# LRFDPBE32 register map
Vendor: Texas Instruments
Peripheral module from a debugger description file (folder CC27xxx10).
Registers are 32-bit, access per field, reset 0x0 unless marked. A register's access mark holds for its fields unless they carry their own. Offsets are as the file gives them; lines under a group give offsets from that group; [hi:lo] are bit positions; {n}, {i} and the like mark numbered series; 'fields as' and 'values as' point back to an identical list; <NAME> marks a mode.

## LRFDPBE32
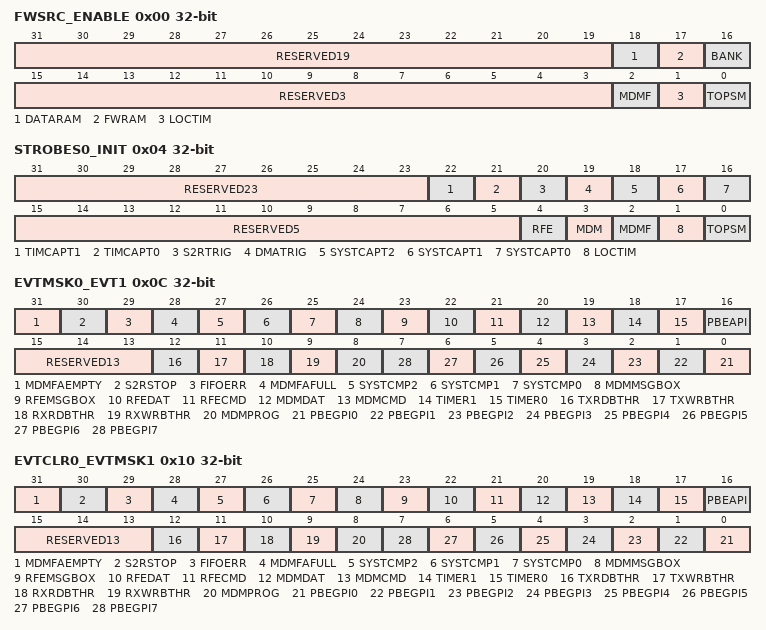
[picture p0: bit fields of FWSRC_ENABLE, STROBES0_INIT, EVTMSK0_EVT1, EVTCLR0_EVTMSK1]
0x00 FWSRC_ENABLE — Internal. Only to be used through TI provided API.
  [31:19] RESERVED19 ro — Internal. Only to be used through TI provided API.
  [18] DATARAM rw — Internal. Only to be used through TI provided API.
    1=S2RRAM (Internal. Only to be used through TI provided API.); 0=PBERAM (Internal. Only to be used through TI provided API.)
  [17] FWRAM rw — Internal. Only to be used through TI provided API.
    values as DATARAM
  [16] BANK rw — Internal. Only to be used through TI provided API.
    1=ONE (Internal. Only to be used through TI provided API.); 0=ZERO (Internal. Only to be used through TI provided API.)
  [15:3] RESERVED3 ro — Internal. Only to be used through TI provided API.
  [2] MDMF rw — Internal. Only to be used through TI provided API.
    1=EN (Internal. Only to be used through TI provided API.); 0=DIS (Internal. Only to be used through TI provided API.)
  [1] LOCTIM rw — Internal. Only to be used through TI provided API.
    values as MDMF
  [0] TOPSM rw — Internal. Only to be used through TI provided API.
    values as MDMF
0x04 STROBES0_INIT — Internal. Only to be used through TI provided API.
  [31:23] RESERVED23 ro — Internal. Only to be used through TI provided API.
  [22] TIMCAPT1 wo — Internal. Only to be used through TI provided API.
    values as FWSRC_ENABLE.BANK
  [21] TIMCAPT0 wo — Internal. Only to be used through TI provided API.
    values as FWSRC_ENABLE.BANK
  [20] S2RTRIG wo — Internal. Only to be used through TI provided API.
    1=ARM (Internal. Only to be used through TI provided API.); 0=NO_EFFECT (Internal. Only to be used through TI provided API.)
  [19] DMATRIG wo — Internal. Only to be used through TI provided API.
    values as S2RTRIG
  [18] SYSTCAPT2 wo — Internal. Only to be used through TI provided API.
    values as FWSRC_ENABLE.BANK
  [17] SYSTCAPT1 wo — Internal. Only to be used through TI provided API.
    values as FWSRC_ENABLE.BANK
  [16] SYSTCAPT0 wo — Internal. Only to be used through TI provided API.
    values as FWSRC_ENABLE.BANK
  [15:5] RESERVED5 ro — Internal. Only to be used through TI provided API.
  [4] RFE wo — Internal. Only to be used through TI provided API.
    1=RESET (Internal. Only to be used through TI provided API.); 0=NO_EFFECT (Internal. Only to be used through TI provided API.)
  [3] MDM wo — Internal. Only to be used through TI provided API.
    values as RFE
  [2] MDMF wo — Internal. Only to be used through TI provided API.
    values as RFE
  [1] LOCTIM wo — Internal. Only to be used through TI provided API.
    values as RFE
  [0] TOPSM wo — Internal. Only to be used through TI provided API.
    values as RFE
0x08 EVT0_IRQ — Internal. Only to be used through TI provided API.
  [31] MDMFAEMPTY ro — Internal. Only to be used through TI provided API.
    values as FWSRC_ENABLE.BANK
  [30] S2RSTOP ro — Internal. Only to be used through TI provided API.
    values as FWSRC_ENABLE.BANK
  [29] FIFOERR ro — Internal. Only to be used through TI provided API.
    values as FWSRC_ENABLE.BANK
  [28] MDMFAFULL ro — Internal. Only to be used through TI provided API.
    values as FWSRC_ENABLE.BANK
  [27] SYSTCMP2 ro — Internal. Only to be used through TI provided API.
    values as FWSRC_ENABLE.BANK
  [26] SYSTCMP1 ro — Internal. Only to be used through TI provided API.
    values as FWSRC_ENABLE.BANK
  [25] SYSTCMP0 ro — Internal. Only to be used through TI provided API.
    values as FWSRC_ENABLE.BANK
  [24] MDMMSGBOX ro — Internal. Only to be used through TI provided API.
    values as FWSRC_ENABLE.BANK
  [23] RFEMSGBOX ro — Internal. Only to be used through TI provided API.
    values as FWSRC_ENABLE.BANK
  [22] RFEDAT ro — Internal. Only to be used through TI provided API.
    values as FWSRC_ENABLE.BANK
  [21] RFECMD ro — Internal. Only to be used through TI provided API.
    values as FWSRC_ENABLE.BANK
  [20] MDMDAT ro — Internal. Only to be used through TI provided API.
    values as FWSRC_ENABLE.BANK
  [19] MDMCMD ro — Internal. Only to be used through TI provided API.
    values as FWSRC_ENABLE.BANK
  [18] TIMER1 ro — Internal. Only to be used through TI provided API.
    values as FWSRC_ENABLE.BANK
  [17] TIMER0 ro — Internal. Only to be used through TI provided API.
    values as FWSRC_ENABLE.BANK
  [16] PBEAPI ro — Internal. Only to be used through TI provided API.
    values as FWSRC_ENABLE.BANK
  [n] SOFT{n} wo (n=0..15) — Internal. Only to be used through TI provided API.
    1=ON (Internal. Only to be used through TI provided API.); 0=OFF (Internal. Only to be used through TI provided API.)
  [9:0] RESERVED0 ro — Internal. Only to be used through TI provided API.
0x0C EVTMSK0_EVT1 — Internal. Only to be used through TI provided API.
  [31] MDMFAEMPTY rw — Internal. Only to be used through TI provided API.
    values as FWSRC_ENABLE.MDMF
  [30] S2RSTOP rw — Internal. Only to be used through TI provided API.
    values as FWSRC_ENABLE.MDMF
  [29] FIFOERR rw — Internal. Only to be used through TI provided API.
    values as FWSRC_ENABLE.MDMF
  [28] MDMFAFULL rw — Internal. Only to be used through TI provided API.
    values as FWSRC_ENABLE.MDMF
  [27] SYSTCMP2 rw — Internal. Only to be used through TI provided API.
    values as FWSRC_ENABLE.MDMF
  [26] SYSTCMP1 rw — Internal. Only to be used through TI provided API.
    values as FWSRC_ENABLE.MDMF
  [25] SYSTCMP0 rw — Internal. Only to be used through TI provided API.
    values as FWSRC_ENABLE.MDMF
  [24] MDMMSGBOX rw — Internal. Only to be used through TI provided API.
    values as FWSRC_ENABLE.MDMF
  [23] RFEMSGBOX rw — Internal. Only to be used through TI provided API.
    values as FWSRC_ENABLE.MDMF
  [22] RFEDAT rw — Internal. Only to be used through TI provided API.
    values as FWSRC_ENABLE.MDMF
  [21] RFECMD rw — Internal. Only to be used through TI provided API.
    values as FWSRC_ENABLE.MDMF
  [20] MDMDAT rw — Internal. Only to be used through TI provided API.
    values as FWSRC_ENABLE.MDMF
  [19] MDMCMD rw — Internal. Only to be used through TI provided API.
    values as FWSRC_ENABLE.MDMF
  [18] TIMER1 rw — Internal. Only to be used through TI provided API.
    values as FWSRC_ENABLE.MDMF
  [17] TIMER0 rw — Internal. Only to be used through TI provided API.
    values as FWSRC_ENABLE.MDMF
  [16] PBEAPI rw — Internal. Only to be used through TI provided API.
    values as FWSRC_ENABLE.MDMF
  [15:13] RESERVED13 ro — Internal. Only to be used through TI provided API.
  [12] TXRDBTHR ro — Internal. Only to be used through TI provided API.
    1=MET (Internal. Only to be used through TI provided API.); 0=BELOW (Internal. Only to be used through TI provided API.)
  [11] TXWRBTHR ro — Internal. Only to be used through TI provided API.
    values as TXRDBTHR
  [10] RXRDBTHR ro — Internal. Only to be used through TI provided API.
    values as TXRDBTHR
  [9] RXWRBTHR ro — Internal. Only to be used through TI provided API.
    values as TXRDBTHR
  [8] MDMPROG ro — Internal. Only to be used through TI provided API.
    values as FWSRC_ENABLE.BANK
  [n] PBEGPI{n} ro (n=0..7) — Internal. Only to be used through TI provided API.
    values as FWSRC_ENABLE.BANK
0x10 EVTCLR0_EVTMSK1 — Internal. Only to be used through TI provided API.
  [31] MDMFAEMPTY wo — Internal. Only to be used through TI provided API.
    1=CLEAR (Internal. Only to be used through TI provided API.); 0=RETAIN (Internal. Only to be used through TI provided API.)
  [30] S2RSTOP wo — Internal. Only to be used through TI provided API.
    values as MDMFAEMPTY
  [29] FIFOERR wo — Internal. Only to be used through TI provided API.
    values as MDMFAEMPTY
  [28] MDMFAFULL wo — Internal. Only to be used through TI provided API.
    values as MDMFAEMPTY
  [27] SYSTCMP2 wo — Internal. Only to be used through TI provided API.
    values as MDMFAEMPTY
  [26] SYSTCMP1 wo — Internal. Only to be used through TI provided API.
    values as MDMFAEMPTY
  [25] SYSTCMP0 wo — Internal. Only to be used through TI provided API.
    values as MDMFAEMPTY
  [24] MDMMSGBOX wo — Internal. Only to be used through TI provided API.
    values as MDMFAEMPTY
  [23] RFEMSGBOX wo — Internal. Only to be used through TI provided API.
    values as MDMFAEMPTY
  [22] RFEDAT wo — Internal. Only to be used through TI provided API.
    values as MDMFAEMPTY
  [21] RFECMD wo — Internal. Only to be used through TI provided API.
    values as MDMFAEMPTY
  [20] MDMDAT wo — Internal. Only to be used through TI provided API.
    values as MDMFAEMPTY
  [19] MDMCMD wo — Internal. Only to be used through TI provided API.
    values as MDMFAEMPTY
  [18] TIMER1 wo — Internal. Only to be used through TI provided API.
    values as MDMFAEMPTY
  [17] TIMER0 wo — Internal. Only to be used through TI provided API.
    values as MDMFAEMPTY
  [16] PBEAPI wo — Internal. Only to be used through TI provided API.
    values as MDMFAEMPTY
  [15:13] RESERVED13 ro — Internal. Only to be used through TI provided API.
  [12] TXRDBTHR rw — Internal. Only to be used through TI provided API.
    values as FWSRC_ENABLE.MDMF
  [11] TXWRBTHR rw — Internal. Only to be used through TI provided API.
    values as FWSRC_ENABLE.MDMF
  [10] RXRDBTHR rw — Internal. Only to be used through TI provided API.
    values as FWSRC_ENABLE.MDMF
  [9] RXWRBTHR rw — Internal. Only to be used through TI provided API.
    values as FWSRC_ENABLE.MDMF
  [8] MDMPROG rw — Internal. Only to be used through TI provided API.
    values as FWSRC_ENABLE.MDMF
  [n] PBEGPI{n} rw (n=0..7) — Internal. Only to be used through TI provided API.
    values as FWSRC_ENABLE.MDMF
0x14 PDREQ_EVTCLR1 — Internal. Only to be used through TI provided API.
  [31:17] RESERVED17 ro — Internal. Only to be used through TI provided API.
  [16] TOPSMPDREQ rw — Internal. Only to be used through TI provided API.
    values as EVT0_IRQ.SOFT0
  [15:13] RESERVED13 ro — Internal. Only to be used through TI provided API.
  [12] TXRDBTHR wo — Internal. Only to be used through TI provided API.
    values as EVTCLR0_EVTMSK1.MDMFAEMPTY
  [11] TXWRBTHR wo — Internal. Only to be used through TI provided API.
    values as EVTCLR0_EVTMSK1.MDMFAEMPTY
  [10] RXRDBTHR wo — Internal. Only to be used through TI provided API.
    values as EVTCLR0_EVTMSK1.MDMFAEMPTY
  [9] RXWRBTHR wo — Internal. Only to be used through TI provided API.
    values as EVTCLR0_EVTMSK1.MDMFAEMPTY
  [8] MDMPROG wo — Internal. Only to be used through TI provided API.
    values as EVTCLR0_EVTMSK1.MDMFAEMPTY
  [n] PBEGPI{n} wo (n=0..7) — Internal. Only to be used through TI provided API.
    values as EVTCLR0_EVTMSK1.MDMFAEMPTY
  [6] RESERVED6 ro — Internal. Only to be used through TI provided API.
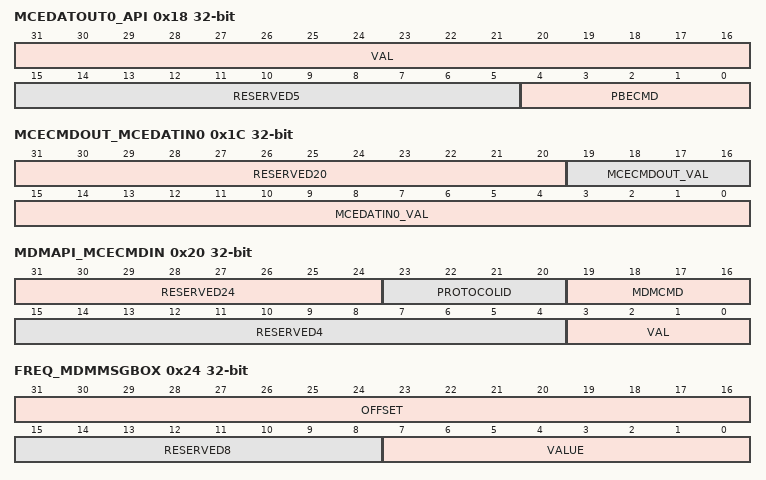
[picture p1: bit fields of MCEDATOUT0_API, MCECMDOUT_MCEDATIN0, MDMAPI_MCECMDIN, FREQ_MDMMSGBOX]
0x18 MCEDATOUT0_API — Internal. Only to be used through TI provided API.
  [31:16] VAL rw — Internal. Only to be used through TI provided API.
    0xFFFF=ALLONES (Internal. Only to be used through TI provided API.); 0=ALLZEROS (Internal. Only to be used through TI provided API.)
  [15:5] RESERVED5 ro — Internal. Only to be used through TI provided API.
  [4:0] PBECMD rw — Internal. Only to be used through TI provided API.
    31=ALLONES (Internal. Only to be used through TI provided API.); 0=ALLZEROS (Internal. Only to be used through TI provided API.)
0x1C MCECMDOUT_MCEDATIN0 — Internal. Only to be used through TI provided API.
  [31:20] RESERVED20 ro — Internal. Only to be used through TI provided API.
  [19:16] MCECMDOUT_VAL rw — Internal. Only to be used through TI provided API.
    15=ALLONES (Internal. Only to be used through TI provided API.); 0=ALLZEROS (Internal. Only to be used through TI provided API.)
  [15:0] MCEDATIN0_VAL ro — Internal. Only to be used through TI provided API.
    values as MCEDATOUT0_API.VAL
0x20 MDMAPI_MCECMDIN — Internal. Only to be used through TI provided API.
  [31:24] RESERVED24 ro — Internal. Only to be used through TI provided API.
  [23:20] PROTOCOLID rw — Internal. Only to be used through TI provided API.
    values as MCECMDOUT_MCEDATIN0.MCECMDOUT_VAL
  [19:16] MDMCMD rw — Internal. Only to be used through TI provided API.
    values as MCECMDOUT_MCEDATIN0.MCECMDOUT_VAL
  [15:4] RESERVED4 ro — Internal. Only to be used through TI provided API.
  [3:0] VAL ro — Internal. Only to be used through TI provided API.
    values as MCECMDOUT_MCEDATIN0.MCECMDOUT_VAL
0x24 FREQ_MDMMSGBOX ro — Internal. Only to be used through TI provided API.
  [31:16] OFFSET — Internal. Only to be used through TI provided API.
    values as MCEDATOUT0_API.VAL
  [15:8] RESERVED8 — Internal. Only to be used through TI provided API.
  [7:0] VALUE — Internal. Only to be used through TI provided API.
    255=ALLONES (Internal. Only to be used through TI provided API.); 0=ALLZEROS (Internal. Only to be used through TI provided API.)
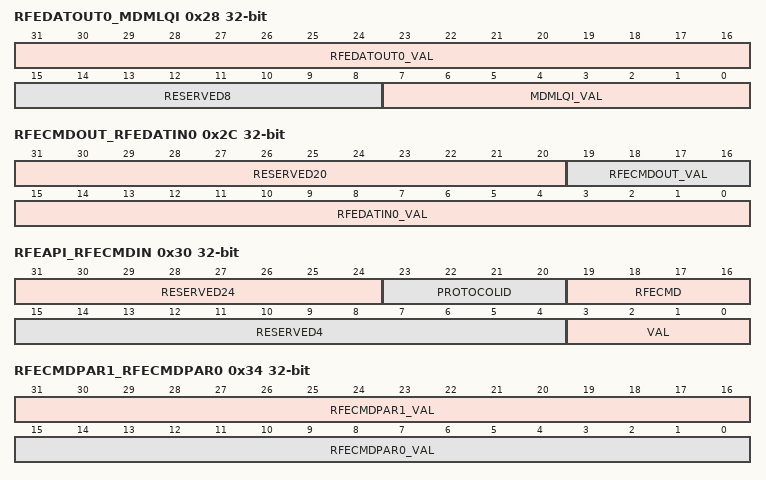
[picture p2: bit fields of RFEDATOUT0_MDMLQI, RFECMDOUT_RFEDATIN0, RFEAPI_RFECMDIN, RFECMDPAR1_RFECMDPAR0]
0x28 RFEDATOUT0_MDMLQI — Internal. Only to be used through TI provided API.
  [31:16] RFEDATOUT0_VAL rw — Internal. Only to be used through TI provided API.
    values as MCEDATOUT0_API.VAL
  [15:8] RESERVED8 ro — Internal. Only to be used through TI provided API.
  [7:0] MDMLQI_VAL ro — Internal. Only to be used through TI provided API.
    values as FREQ_MDMMSGBOX.VALUE
0x2C RFECMDOUT_RFEDATIN0 — Internal. Only to be used through TI provided API.
  [31:20] RESERVED20 ro — Internal. Only to be used through TI provided API.
  [19:16] RFECMDOUT_VAL rw — Internal. Only to be used through TI provided API.
    values as MCECMDOUT_MCEDATIN0.MCECMDOUT_VAL
  [15:0] RFEDATIN0_VAL ro — Internal. Only to be used through TI provided API.
    values as MCEDATOUT0_API.VAL
0x30 RFEAPI_RFECMDIN — Internal. Only to be used through TI provided API.
  [31:24] RESERVED24 ro — Internal. Only to be used through TI provided API.
  [23:20] PROTOCOLID rw — Internal. Only to be used through TI provided API.
    values as MCECMDOUT_MCEDATIN0.MCECMDOUT_VAL
  [19:16] RFECMD rw — Internal. Only to be used through TI provided API.
    values as MCECMDOUT_MCEDATIN0.MCECMDOUT_VAL
  [15:4] RESERVED4 ro — Internal. Only to be used through TI provided API.
  [3:0] VAL ro — Internal. Only to be used through TI provided API.
    values as MCECMDOUT_MCEDATIN0.MCECMDOUT_VAL
0x34 RFECMDPAR1_RFECMDPAR0 rw — Internal. Only to be used through TI provided API.
  [31:16] RFECMDPAR1_VAL — Internal. Only to be used through TI provided API.
    values as MCEDATOUT0_API.VAL
  [15:0] RFECMDPAR0_VAL — Internal. Only to be used through TI provided API.
    values as MCEDATOUT0_API.VAL
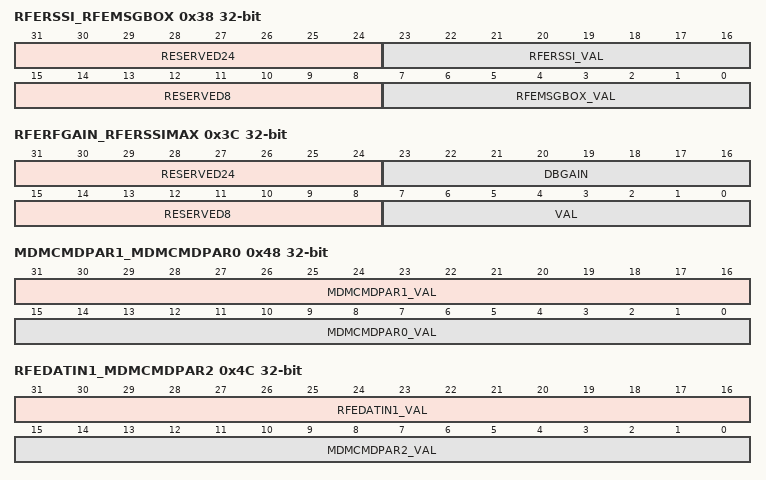
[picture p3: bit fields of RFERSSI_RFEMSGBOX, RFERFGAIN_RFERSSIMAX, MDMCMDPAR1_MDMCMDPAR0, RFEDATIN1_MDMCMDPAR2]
0x38 RFERSSI_RFEMSGBOX ro — Internal. Only to be used through TI provided API.
  [31:24] RESERVED24 — Internal. Only to be used through TI provided API.
  [23:16] RFERSSI_VAL — Internal. Only to be used through TI provided API.
    values as FREQ_MDMMSGBOX.VALUE
  [15:8] RESERVED8 — Internal. Only to be used through TI provided API.
  [7:0] RFEMSGBOX_VAL — Internal. Only to be used through TI provided API.
    values as FREQ_MDMMSGBOX.VALUE
0x3C RFERFGAIN_RFERSSIMAX ro — Internal. Only to be used through TI provided API.
  [31:24] RESERVED24 — Internal. Only to be used through TI provided API.
  [23:16] DBGAIN — Internal. Only to be used through TI provided API.
    values as FREQ_MDMMSGBOX.VALUE
  [15:8] RESERVED8 — Internal. Only to be used through TI provided API.
  [7:0] VAL — Internal. Only to be used through TI provided API.
    values as FREQ_MDMMSGBOX.VALUE
0x40 MDMSYNCA rw — Internal. Only to be used through TI provided API.
  [31:0] SWA
    values as MCEDATOUT0_API.VAL
0x44 MDMSYNCB rw — Internal. Only to be used through TI provided API.
  [31:0] SWB
    values as MCEDATOUT0_API.VAL
0x48 MDMCMDPAR1_MDMCMDPAR0 rw — Internal. Only to be used through TI provided API.
  [31:16] MDMCMDPAR1_VAL — Internal. Only to be used through TI provided API.
    values as MCEDATOUT0_API.VAL
  [15:0] MDMCMDPAR0_VAL — Internal. Only to be used through TI provided API.
    values as MCEDATOUT0_API.VAL
0x4C RFEDATIN1_MDMCMDPAR2 — Internal. Only to be used through TI provided API.
  [31:16] RFEDATIN1_VAL ro — Internal. Only to be used through TI provided API.
    values as MCEDATOUT0_API.VAL
  [15:0] MDMCMDPAR2_VAL rw — Internal. Only to be used through TI provided API.
    values as MCEDATOUT0_API.VAL
0x50 POLY0 rw — Internal. Only to be used through TI provided API.
  [31:0] VAL
    values as MCEDATOUT0_API.VAL
0x54 POLY1 rw — Internal. Only to be used through TI provided API.
  fields as POLY0
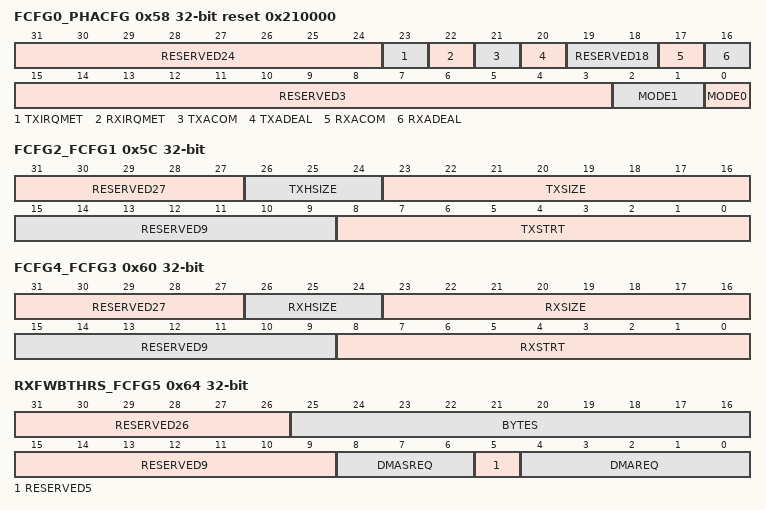
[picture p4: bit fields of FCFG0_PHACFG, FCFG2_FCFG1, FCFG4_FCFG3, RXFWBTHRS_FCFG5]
0x58 FCFG0_PHACFG reset 0x210000 — Internal. Only to be used through TI provided API.
  [31:24] RESERVED24 ro — Internal. Only to be used through TI provided API.
  [23] TXIRQMET rw — Internal. Only to be used through TI provided API.
    1=TXRDBTHR (Internal. Only to be used through TI provided API.); 0=TXWRBTHR (Internal. Only to be used through TI provided API.)
  [22] RXIRQMET rw — Internal. Only to be used through TI provided API.
    1=RXWRBTHR (Internal. Only to be used through TI provided API.); 0=RXRDBTHR (Internal. Only to be used through TI provided API.)
  [21] TXACOM rw — Internal. Only to be used through TI provided API.
    values as FWSRC_ENABLE.MDMF
  [20] TXADEAL rw — Internal. Only to be used through TI provided API.
    values as FWSRC_ENABLE.MDMF
  [19:18] RESERVED18 ro — Internal. Only to be used through TI provided API.
  [17] RXACOM rw — Internal. Only to be used through TI provided API.
    values as FWSRC_ENABLE.MDMF
  [16] RXADEAL rw — Internal. Only to be used through TI provided API.
    values as FWSRC_ENABLE.MDMF
  [15:3] RESERVED3 ro — Internal. Only to be used through TI provided API.
  [2:1] MODE1 rw — Internal. Only to be used through TI provided API.
    2=PARAL (Internal. Only to be used through TI provided API.); 1=CASC (Internal. Only to be used through TI provided API.); 0=INDEP (Internal. Only to be used through TI provided API.)
  [0] MODE0 rw — Internal. Only to be used through TI provided API.
    1=WHITE (Internal. Only to be used through TI provided API.); 0=CRC (Internal. Only to be used through TI provided API.)
0x5C FCFG2_FCFG1 — Internal. Only to be used through TI provided API.
  [31:27] RESERVED27 ro — Internal. Only to be used through TI provided API.
  [26:24] TXHSIZE rw — Internal. Only to be used through TI provided API.
    2=WORD (Internal. Only to be used through TI provided API.); 1=HALFW (Internal. Only to be used through TI provided API.); 0=BYTE (Internal. Only to be used through TI provided API.)
  [23:16] TXSIZE rw — Internal. Only to be used through TI provided API.
    255=ONES (Internal. Only to be used through TI provided API.); 0=ZEROS (Internal. Only to be used through TI provided API.)
  [15:9] RESERVED9 ro — Internal. Only to be used through TI provided API.
  [8:0] TXSTRT rw — Internal. Only to be used through TI provided API.
    0x1FF=ONES (Internal. Only to be used through TI provided API.); 0=ZEROS (Internal. Only to be used through TI provided API.)
0x60 FCFG4_FCFG3 — Internal. Only to be used through TI provided API.
  [31:27] RESERVED27 ro — Internal. Only to be used through TI provided API.
  [26:24] RXHSIZE rw — Internal. Only to be used through TI provided API.
    values as FCFG2_FCFG1.TXHSIZE
  [23:16] RXSIZE rw — Internal. Only to be used through TI provided API.
    values as FCFG2_FCFG1.TXSIZE
  [15:9] RESERVED9 ro — Internal. Only to be used through TI provided API.
  [8:0] RXSTRT rw — Internal. Only to be used through TI provided API.
    values as FCFG2_FCFG1.TXSTRT
0x64 RXFWBTHRS_FCFG5 — Internal. Only to be used through TI provided API.
  [31:26] RESERVED26 ro — Internal. Only to be used through TI provided API.
  [25:16] BYTES rw — Internal. Only to be used through TI provided API.
    0x3FF=ALLONES (Internal. Only to be used through TI provided API.); 0=ALLZEROS (Internal. Only to be used through TI provided API.)
  [15:9] RESERVED9 ro — Internal. Only to be used through TI provided API.
  [8:6] DMASREQ rw — Internal. Only to be used through TI provided API.
    4=TXFIFOFREE (Internal. Only to be used through TI provided API.); 3=TXFIFOMD (Internal. Only to be used through TI provided API.); 2=RXFIFOFREE (Internal. Only to be used through TI provided API.); 1=RXFIFOMD (Internal. Only to be used through TI provided API.); 0=NONE (Internal. Only to be used through TI provided API.)
  [5] RESERVED5 ro — Internal. Only to be used through TI provided API.
  [4:0] DMAREQ rw — Internal. Only to be used through TI provided API.
    15=TXFIFO_COMMIT (Internal. Only to be used through TI provided API.); 14=TXFIFO_DISCARD (Internal. Only to be used through TI provided API.); 13=TXFIFO_RETRY (Internal. Only to be used through TI provided API.); 12=TXFIFO_DEALLOC (Internal. Only to be used through TI provided API.); 11=TXFIFO_RESET (Internal. Only to be used through TI provided API.); 10=TXWRBTHR_MET (Internal. Only to be used through TI provided API.); 9=TXRDBTHR_MET (Internal. Only to be used through TI provided API.); 7=RXFIFO_COMMIT (Internal. Only to be used through TI provided API.); 6=RXFIFO_DISCARD (Internal. Only to be used through TI provided API.); 5=RXFIFO_RETRY (Internal. Only to be used through TI provided API.); 4=RXFIFO_DEALLOC (Internal. Only to be used through TI provided API.); 3=RXFIFO_RESET (Internal. Only to be used through TI provided API.); 2=RXWRBTHR_MET (Internal. Only to be used through TI provided API.); 1=RXRDBTHR_MET (Internal. Only to be used through TI provided API.); 0=NONE (Internal. Only to be used through TI provided API.)
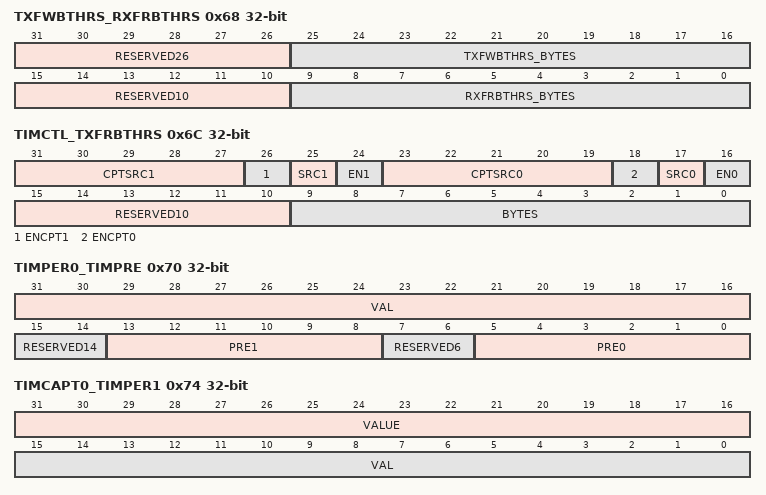
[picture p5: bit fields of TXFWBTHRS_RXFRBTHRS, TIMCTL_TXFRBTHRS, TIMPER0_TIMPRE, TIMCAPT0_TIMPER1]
0x68 TXFWBTHRS_RXFRBTHRS — Internal. Only to be used through TI provided API.
  [31:26] RESERVED26 ro — Internal. Only to be used through TI provided API.
  [25:16] TXFWBTHRS_BYTES rw — Internal. Only to be used through TI provided API.
    values as RXFWBTHRS_FCFG5.BYTES
  [15:10] RESERVED10 ro — Internal. Only to be used through TI provided API.
  [9:0] RXFRBTHRS_BYTES rw — Internal. Only to be used through TI provided API.
    values as RXFWBTHRS_FCFG5.BYTES
0x6C TIMCTL_TXFRBTHRS — Internal. Only to be used through TI provided API.
  [31:27] CPTSRC1 rw — Internal. Only to be used through TI provided API.
    values as MCEDATOUT0_API.PBECMD
  [26] ENCPT1 rw — Internal. Only to be used through TI provided API.
    values as EVT0_IRQ.SOFT0
  [25] SRC1 rw — Internal. Only to be used through TI provided API.
    1=PRE1 (Internal. Only to be used through TI provided API.); 0=CLK (Internal. Only to be used through TI provided API.)
  [24] EN1 rw — Internal. Only to be used through TI provided API.
    values as EVT0_IRQ.SOFT0
  [23:19] CPTSRC0 rw — Internal. Only to be used through TI provided API.
    values as MCEDATOUT0_API.PBECMD
  [18] ENCPT0 rw — Internal. Only to be used through TI provided API.
    values as EVT0_IRQ.SOFT0
  [17] SRC0 rw — Internal. Only to be used through TI provided API.
    1=PRE0 (Internal. Only to be used through TI provided API.); 0=CLK (Internal. Only to be used through TI provided API.)
  [16] EN0 rw — Internal. Only to be used through TI provided API.
    values as EVT0_IRQ.SOFT0
  [15:10] RESERVED10 ro — Internal. Only to be used through TI provided API.
  [9:0] BYTES rw — Internal. Only to be used through TI provided API.
    values as RXFWBTHRS_FCFG5.BYTES
0x70 TIMPER0_TIMPRE — Internal. Only to be used through TI provided API.
  [31:16] VAL rw — Internal. Only to be used through TI provided API.
    values as MCEDATOUT0_API.VAL
  [15:14] RESERVED14 ro — Internal. Only to be used through TI provided API.
  [13:8] PRE1 rw — Internal. Only to be used through TI provided API.
    63=DIV64 (Internal. Only to be used through TI provided API.); 0=NO_DIV (Internal. Only to be used through TI provided API.)
  [7:6] RESERVED6 ro — Internal. Only to be used through TI provided API.
  [5:0] PRE0 rw — Internal. Only to be used through TI provided API.
    values as PRE1
0x74 TIMCAPT0_TIMPER1 — Internal. Only to be used through TI provided API.
  [31:16] VALUE ro — Internal. Only to be used through TI provided API.
    values as MCEDATOUT0_API.VAL
  [15:0] VAL rw — Internal. Only to be used through TI provided API.
    values as MCEDATOUT0_API.VAL
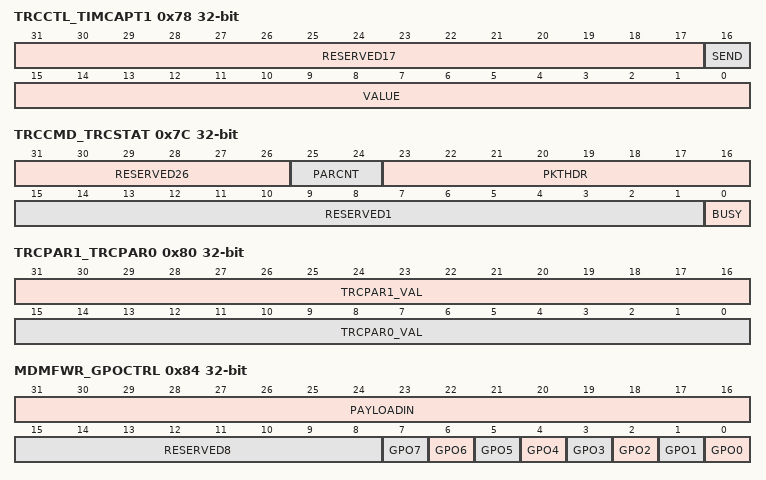
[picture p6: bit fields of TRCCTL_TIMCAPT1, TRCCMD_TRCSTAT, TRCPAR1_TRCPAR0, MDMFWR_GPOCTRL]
0x78 TRCCTL_TIMCAPT1 — Internal. Only to be used through TI provided API.
  [31:17] RESERVED17 ro — Internal. Only to be used through TI provided API.
  [16] SEND wo — Internal. Only to be used through TI provided API.
    values as FWSRC_ENABLE.BANK
  [15:0] VALUE ro — Internal. Only to be used through TI provided API.
    values as MCEDATOUT0_API.VAL
0x7C TRCCMD_TRCSTAT — Internal. Only to be used through TI provided API.
  [31:26] RESERVED26 ro — Internal. Only to be used through TI provided API.
  [25:24] PARCNT rw — Internal. Only to be used through TI provided API.
    3=ALLONES (Internal. Only to be used through TI provided API.); 0=ALLZEROS (Internal. Only to be used through TI provided API.)
  [23:16] PKTHDR rw — Internal. Only to be used through TI provided API.
    values as FREQ_MDMMSGBOX.VALUE
  [15:1] RESERVED1 ro — Internal. Only to be used through TI provided API.
  [0] BUSY ro — Internal. Only to be used through TI provided API.
    values as FWSRC_ENABLE.BANK
0x80 TRCPAR1_TRCPAR0 rw — Internal. Only to be used through TI provided API.
  [31:16] TRCPAR1_VAL — Internal. Only to be used through TI provided API.
    values as MCEDATOUT0_API.VAL
  [15:0] TRCPAR0_VAL — Internal. Only to be used through TI provided API.
    values as MCEDATOUT0_API.VAL
0x84 MDMFWR_GPOCTRL — Internal. Only to be used through TI provided API.
  [31:16] PAYLOADIN rw — Internal. Only to be used through TI provided API.
    values as MCEDATOUT0_API.VAL
  [15:8] RESERVED8 ro — Internal. Only to be used through TI provided API.
  [n] GPO{n} rw (n=0..7) — Internal. Only to be used through TI provided API.
    values as FWSRC_ENABLE.BANK
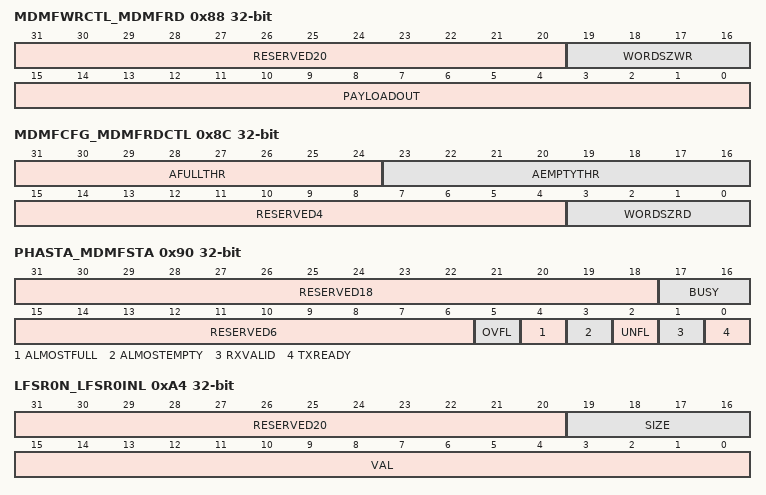
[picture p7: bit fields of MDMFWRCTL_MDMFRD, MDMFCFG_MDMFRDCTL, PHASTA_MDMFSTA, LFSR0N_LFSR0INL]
0x88 MDMFWRCTL_MDMFRD — Internal. Only to be used through TI provided API.
  [31:20] RESERVED20 ro — Internal. Only to be used through TI provided API.
  [19:16] WORDSZWR rw — Internal. Only to be used through TI provided API.
    {v}=BITS{v+1} (Internal. Only to be used through TI provided API.) (v=0..15)
  [15:0] PAYLOADOUT ro — Internal. Only to be used through TI provided API.
    values as MCEDATOUT0_API.VAL
0x8C MDMFCFG_MDMFRDCTL — Internal. Only to be used through TI provided API.
  [31:24] AFULLTHR rw — Internal. Only to be used through TI provided API.
    values as FREQ_MDMMSGBOX.VALUE
  [23:16] AEMPTYTHR rw — Internal. Only to be used through TI provided API.
    values as FREQ_MDMMSGBOX.VALUE
  [15:4] RESERVED4 ro — Internal. Only to be used through TI provided API.
  [3:0] WORDSZRD rw — Internal. Only to be used through TI provided API.
    values as MDMFWRCTL_MDMFRD.WORDSZWR
0x90 PHASTA_MDMFSTA ro — Internal. Only to be used through TI provided API.
  [31:18] RESERVED18 — Internal. Only to be used through TI provided API.
  [17:16] BUSY — Internal. Only to be used through TI provided API.
    1=BUSY (Internal. Only to be used through TI provided API.); 0=IDLE (Internal. Only to be used through TI provided API.)
  [15:6] RESERVED6 — Internal. Only to be used through TI provided API.
  [5] OVFL — Internal. Only to be used through TI provided API.
    values as FWSRC_ENABLE.BANK
  [4] ALMOSTFULL — Internal. Only to be used through TI provided API.
    values as FWSRC_ENABLE.BANK
  [3] ALMOSTEMPTY — Internal. Only to be used through TI provided API.
    values as FWSRC_ENABLE.BANK
  [2] UNFL — Internal. Only to be used through TI provided API.
    values as FWSRC_ENABLE.BANK
  [1] RXVALID — Internal. Only to be used through TI provided API.
    values as FWSRC_ENABLE.BANK
  [0] TXREADY — Internal. Only to be used through TI provided API.
    values as FWSRC_ENABLE.BANK
0x94 LFSR0 rw reset 0xFFFFFFFF — Internal. Only to be used through TI provided API.
  fields as POLY0
0x98 LFSR0BR rw reset 0xFFFFFFFF — Internal. Only to be used through TI provided API.
  fields as POLY0
0x9C LFSR1 rw reset 0xFFFFFFFF — Internal. Only to be used through TI provided API.
  fields as POLY0
0xA0 LFSR1BR rw reset 0xFFFFFFFF — Internal. Only to be used through TI provided API.
  fields as POLY0
0xA4 LFSR0N_LFSR0INL — Internal. Only to be used through TI provided API.
  [31:20] RESERVED20 ro — Internal. Only to be used through TI provided API.
  [19:16] SIZE rw — Internal. Only to be used through TI provided API.
    values as MCECMDOUT_MCEDATIN0.MCECMDOUT_VAL
  [15:0] VAL wo — Internal. Only to be used through TI provided API.
    values as TRCCMD_TRCSTAT.PARCNT
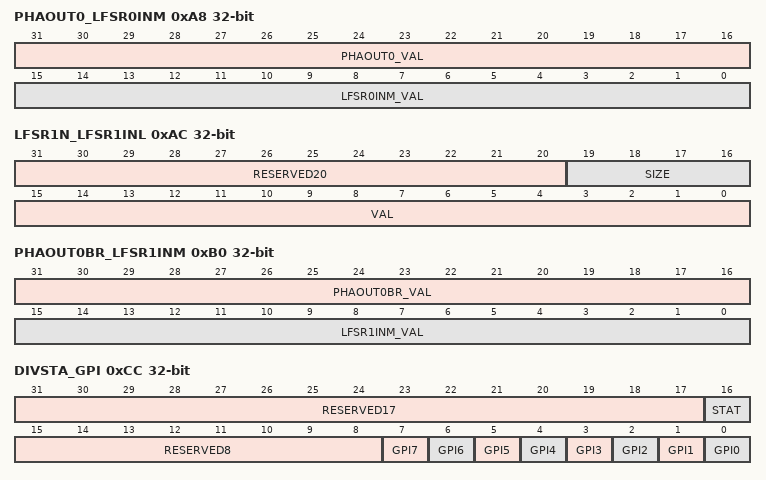
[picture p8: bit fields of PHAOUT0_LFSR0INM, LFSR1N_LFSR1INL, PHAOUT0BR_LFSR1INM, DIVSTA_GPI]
0xA8 PHAOUT0_LFSR0INM — Internal. Only to be used through TI provided API.
  [31:16] PHAOUT0_VAL rw — Internal. Only to be used through TI provided API.
    0xDCD7=ALLONES (Internal. Only to be used through TI provided API.); 0=ALLZEROS (Internal. Only to be used through TI provided API.)
  [15:0] LFSR0INM_VAL wo — Internal. Only to be used through TI provided API.
    values as FWSRC_ENABLE.BANK
0xAC LFSR1N_LFSR1INL — Internal. Only to be used through TI provided API.
  fields as LFSR0N_LFSR0INL
0xB0 PHAOUT0BR_LFSR1INM — Internal. Only to be used through TI provided API.
  [31:16] PHAOUT0BR_VAL ro — Internal. Only to be used through TI provided API.
    values as MCEDATOUT0_API.VAL
  [15:0] LFSR1INM_VAL wo — Internal. Only to be used through TI provided API.
    values as FWSRC_ENABLE.BANK
0xB4 DIVIDEND wo — Internal. Only to be used through TI provided API.
  fields as POLY0
0xB8 DIVISOR rw — Internal. Only to be used through TI provided API.
  fields as POLY0
0xBC QUOTIENT ro — Internal. Only to be used through TI provided API.
  fields as POLY0
{0xC0+4i} SYSTIM{i} ro (i=0..2) — Internal. Only to be used through TI provided API.
  [31:0] VAL
    values as FWSRC_ENABLE.BANK
0xCC DIVSTA_GPI ro — Internal. Only to be used through TI provided API.
  [31:17] RESERVED17 — Internal. Only to be used through TI provided API.
  [16] STAT — Internal. Only to be used through TI provided API.
    values as PHASTA_MDMFSTA.BUSY
  [15:8] RESERVED8 — Internal. Only to be used through TI provided API.
  [n] GPI{n} (n=0..7) — Internal. Only to be used through TI provided API.
    values as FWSRC_ENABLE.BANK
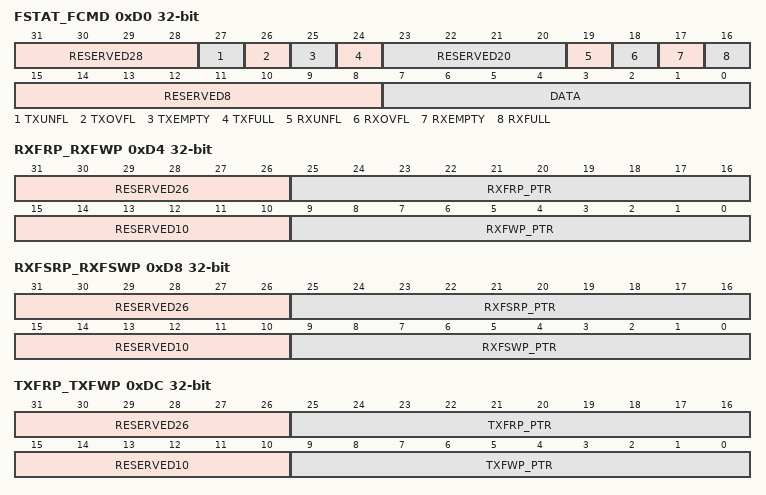
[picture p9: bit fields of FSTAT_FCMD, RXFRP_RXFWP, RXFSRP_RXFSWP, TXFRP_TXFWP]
0xD0 FSTAT_FCMD — Internal. Only to be used through TI provided API.
  [31:28] RESERVED28 ro — Internal. Only to be used through TI provided API.
  [27] TXUNFL ro — Internal. Only to be used through TI provided API.
    1=TRUE (Internal. Only to be used through TI provided API.); 0=FALSE (Internal. Only to be used through TI provided API.)
  [26] TXOVFL ro — Internal. Only to be used through TI provided API.
    values as TXUNFL
  [25] TXEMPTY ro — Internal. Only to be used through TI provided API.
    values as TXUNFL
  [24] TXFULL ro — Internal. Only to be used through TI provided API.
    values as TXUNFL
  [23:20] RESERVED20 ro — Internal. Only to be used through TI provided API.
  [19] RXUNFL ro — Internal. Only to be used through TI provided API.
    values as TXUNFL
  [18] RXOVFL ro — Internal. Only to be used through TI provided API.
    values as TXUNFL
  [17] RXEMPTY ro — Internal. Only to be used through TI provided API.
    values as TXUNFL
  [16] RXFULL ro — Internal. Only to be used through TI provided API.
    values as TXUNFL
  [15:8] RESERVED8 ro — Internal. Only to be used through TI provided API.
  [7:0] DATA wo — Internal. Only to be used through TI provided API.
    15=FIFO_COMMIT (Internal. Only to be used through TI provided API.); 14=FIFO_DISCARD (Internal. Only to be used through TI provided API.); 13=FIFO_RETRY (Internal. Only to be used through TI provided API.); 12=FIFO_DEALLOC (Internal. Only to be used through TI provided API.); 11=FIFO_RESET (Internal. Only to be used through TI provided API.); 10=RXFIFO_RETRY (Internal. Only to be used through TI provided API.); 9=RXFIFO_DISCARD (Internal. Only to be used through TI provided API.); 8=RXFIFO_COMMIT (Internal. Only to be used through TI provided API.); 7=TXFIFO_RESET (Internal. Only to be used through TI provided API.); 6=TXFIFO_DEALLOC (Internal. Only to be used through TI provided API.); 5=TXFIFO_RETRY (Internal. Only to be used through TI provided API.); 4=TXFIFO_DISCARD (Internal. Only to be used through TI provided API.); 3=TXFIFO_COMMIT (Internal. Only to be used through TI provided API.); 2=RXFIFO_DEALLOC (Internal. Only to be used through TI provided API.); 1=RXFIFO_RESET (Internal. Only to be used through TI provided API.)
0xD4 RXFRP_RXFWP — Internal. Only to be used through TI provided API.
  [31:26] RESERVED26 ro — Internal. Only to be used through TI provided API.
  [25:16] RXFRP_PTR rw — Internal. Only to be used through TI provided API.
    values as RXFWBTHRS_FCFG5.BYTES
  [15:10] RESERVED10 ro — Internal. Only to be used through TI provided API.
  [9:0] RXFWP_PTR rw — Internal. Only to be used through TI provided API.
    values as RXFWBTHRS_FCFG5.BYTES
0xD8 RXFSRP_RXFSWP — Internal. Only to be used through TI provided API.
  [31:26] RESERVED26 ro — Internal. Only to be used through TI provided API.
  [25:16] RXFSRP_PTR rw — Internal. Only to be used through TI provided API.
    values as RXFWBTHRS_FCFG5.BYTES
  [15:10] RESERVED10 ro — Internal. Only to be used through TI provided API.
  [9:0] RXFSWP_PTR rw — Internal. Only to be used through TI provided API.
    values as RXFWBTHRS_FCFG5.BYTES
0xDC TXFRP_TXFWP — Internal. Only to be used through TI provided API.
  [31:26] RESERVED26 ro — Internal. Only to be used through TI provided API.
  [25:16] TXFRP_PTR rw — Internal. Only to be used through TI provided API.
    values as RXFWBTHRS_FCFG5.BYTES
  [15:10] RESERVED10 ro — Internal. Only to be used through TI provided API.
  [9:0] TXFWP_PTR rw — Internal. Only to be used through TI provided API.
    values as RXFWBTHRS_FCFG5.BYTES
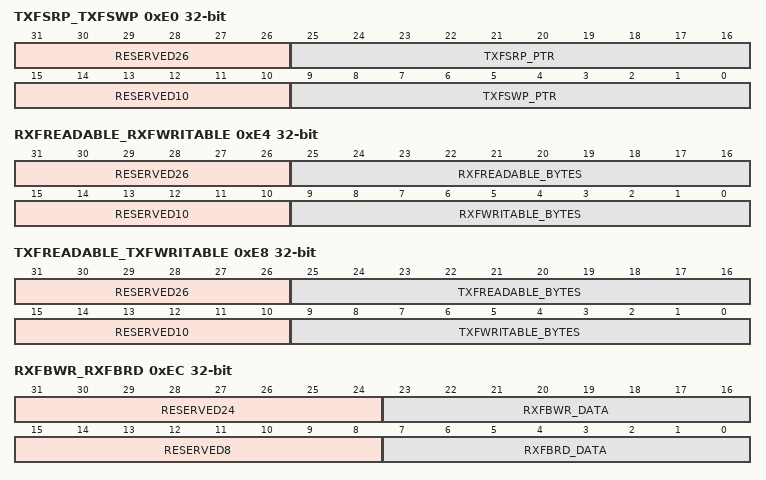
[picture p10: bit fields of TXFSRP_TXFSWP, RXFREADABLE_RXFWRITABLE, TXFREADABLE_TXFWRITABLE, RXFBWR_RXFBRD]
0xE0 TXFSRP_TXFSWP — Internal. Only to be used through TI provided API.
  [31:26] RESERVED26 ro — Internal. Only to be used through TI provided API.
  [25:16] TXFSRP_PTR rw — Internal. Only to be used through TI provided API.
    0x3FF=ALLONES_2 (Internal. Only to be used through TI provided API.); 0=ALLZEROS (Internal. Only to be used through TI provided API.)
  [15:10] RESERVED10 ro — Internal. Only to be used through TI provided API.
  [9:0] TXFSWP_PTR rw — Internal. Only to be used through TI provided API.
    values as RXFWBTHRS_FCFG5.BYTES
0xE4 RXFREADABLE_RXFWRITABLE ro — Internal. Only to be used through TI provided API.
  [31:26] RESERVED26 — Internal. Only to be used through TI provided API.
  [25:16] RXFREADABLE_BYTES — Internal. Only to be used through TI provided API.
    values as RXFWBTHRS_FCFG5.BYTES
  [15:10] RESERVED10 — Internal. Only to be used through TI provided API.
  [9:0] RXFWRITABLE_BYTES — Internal. Only to be used through TI provided API.
    values as RXFWBTHRS_FCFG5.BYTES
0xE8 TXFREADABLE_TXFWRITABLE ro — Internal. Only to be used through TI provided API.
  [31:26] RESERVED26 — Internal. Only to be used through TI provided API.
  [25:16] TXFREADABLE_BYTES — Internal. Only to be used through TI provided API.
    values as RXFWBTHRS_FCFG5.BYTES
  [15:10] RESERVED10 — Internal. Only to be used through TI provided API.
  [9:0] TXFWRITABLE_BYTES — Internal. Only to be used through TI provided API.
    values as RXFWBTHRS_FCFG5.BYTES
0xEC RXFBWR_RXFBRD — Internal. Only to be used through TI provided API.
  [31:24] RESERVED24 ro — Internal. Only to be used through TI provided API.
  [23:16] RXFBWR_DATA wo — Internal. Only to be used through TI provided API.
    values as FREQ_MDMMSGBOX.VALUE
  [15:8] RESERVED8 ro — Internal. Only to be used through TI provided API.
  [7:0] RXFBRD_DATA ro — Internal. Only to be used through TI provided API.
    values as FREQ_MDMMSGBOX.VALUE
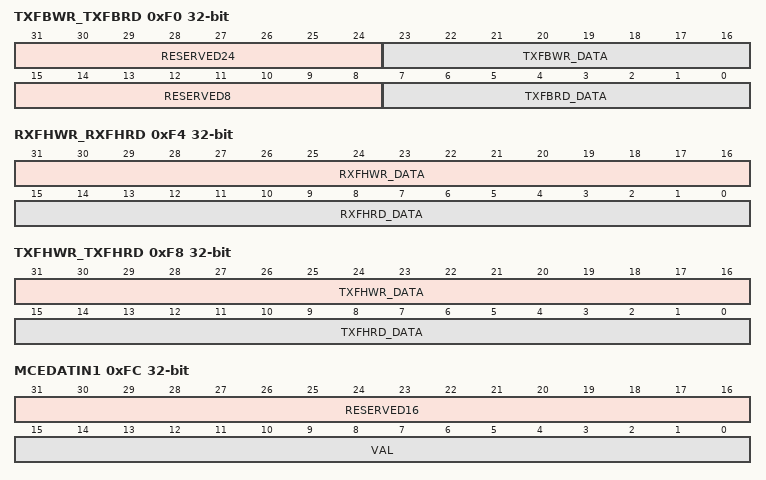
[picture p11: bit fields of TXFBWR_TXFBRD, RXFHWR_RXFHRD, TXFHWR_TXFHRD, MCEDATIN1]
0xF0 TXFBWR_TXFBRD — Internal. Only to be used through TI provided API.
  [31:24] RESERVED24 ro — Internal. Only to be used through TI provided API.
  [23:16] TXFBWR_DATA wo — Internal. Only to be used through TI provided API.
    values as FREQ_MDMMSGBOX.VALUE
  [15:8] RESERVED8 ro — Internal. Only to be used through TI provided API.
  [7:0] TXFBRD_DATA ro — Internal. Only to be used through TI provided API.
    values as FREQ_MDMMSGBOX.VALUE
0xF4 RXFHWR_RXFHRD — Internal. Only to be used through TI provided API.
  [31:16] RXFHWR_DATA wo — Internal. Only to be used through TI provided API.
    values as MCEDATOUT0_API.VAL
  [15:0] RXFHRD_DATA ro — Internal. Only to be used through TI provided API.
    values as MCEDATOUT0_API.VAL
0xF8 TXFHWR_TXFHRD — Internal. Only to be used through TI provided API.
  [31:16] TXFHWR_DATA wo — Internal. Only to be used through TI provided API.
    values as MCEDATOUT0_API.VAL
  [15:0] TXFHRD_DATA ro — Internal. Only to be used through TI provided API.
    values as MCEDATOUT0_API.VAL
0xFC MCEDATIN1 ro — Internal. Only to be used through TI provided API.
  [31:16] RESERVED16 — Internal. Only to be used through TI provided API.
  [15:0] VAL — Internal. Only to be used through TI provided API.
    values as MCEDATOUT0_API.VAL
